# pcm register map
Vendor: Texas Instruments
Peripheral module from a debugger description file (folder MSP432).
Registers are 32-bit, read-write, no defined reset value unless marked. A register's access mark holds for its fields unless they carry their own. Offsets are as the file gives them; lines under a group give offsets from that group; [hi:lo] are bit positions; {n}, {i} and the like mark numbered series; 'fields as' and 'values as' point back to an identical list; <NAME> marks a mode.

## PCM
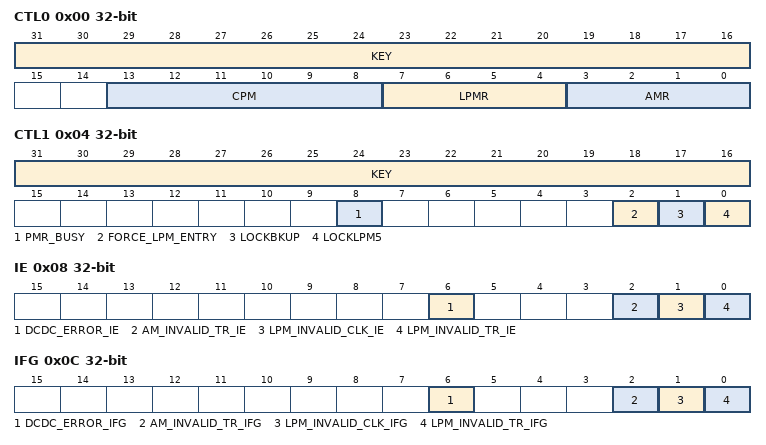
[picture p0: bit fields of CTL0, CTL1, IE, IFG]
0x00 CTL0 — Control 0 Register
  [31:16] KEY — PCM key
  [13:8] CPM — Current Power Mode
    0=CPM__0 (LDO based Active Mode at Core voltage setting 0.); 1=CPM__1 (LDO based Active Mode at Core voltage setting 1.); 4=CPM__4 (DC-DC based Active Mode at Core voltage setting 0.); 5=CPM__5 (DC-DC based Active Mode at Core voltage setting 1.); 8=CPM__8 (Low-Frequency Active Mode at Core voltage setting 0.); 9=CPM__9 (Low-Frequency Active Mode at Core voltage setting 1.); 16=CPM__22 (LDO based LPM0 at Core voltage setting 0.); 17=CPM__23 (LDO based LPM0 at Core voltage setting 1.); 20=CPM__32 (DC-DC based LPM0 at Core voltage setting 0.); 21=CPM__33 (DC-DC based LPM0 at Core voltage setting 1.); 24=CPM__36 (Low-Frequency LPM0 at Core voltage setting 0.); 25=CPM__37 (Low-Frequency LPM0 at Core voltage setting 1.); 32=CPM__50 (LPM3)
  [7:4] LPMR — Low Power Mode Request
    0=LPMR__0 (LPM3); 10=LPMR__16 (LPM3.5. Core voltage setting 0.); 12=LPMR__18 (LPM4.5)
  [3:0] AMR — Active Mode Request
    0=AMR__0 (LDO based Active Mode at Core voltage setting 0.); 1=AMR__1 (LDO based Active Mode at Core voltage setting 1.); 4=AMR__4 (DC-DC based Active Mode at Core voltage setting 0.); 5=AMR__5 (DC-DC based Active Mode at Core voltage setting 1.); 8=AMR__8 (Low-Frequency Active Mode at Core voltage setting 0.); 9=AMR__9 (Low-Frequency Active Mode at Core voltage setting 1.)
0x04 CTL1 — Control 1 Register
  [31:16] KEY — PCM key
  [8] PMR_BUSY — Power mode request busy flag
  [2] FORCE_LPM_ENTRY — Bit selection for the application to determine whether the entr
    0=FORCE_LPM_ENTRY__0 (PCM aborts LPM3/LPMx); 1=FORCE_LPM_ENTRY__1 (PCM enters LPM3/LPMx)
  [1] LOCKBKUP — Lock Backup
    0=LOCKBKUP__0 (Backup domain configuration defaults to reset condition); 1=LOCKBKUP__1 (Backup domain configuration remains locked during LPM3)
  [0] LOCKLPM5
    0=LOCKLPM5__0 (LPMx.5 configuration defaults to reset condition); 1=LOCKLPM5__1 (LPMx.5 configuration remains locked during LPMx.5 entry and exit)
0x08 IE — Interrupt Enable Register
  [6] DCDC_ERROR_IE — DC-DC error interrupt enable
    0=DCDC_ERROR_IE__0 (Disabled); 1=DCDC_ERROR_IE__1 (Enabled)
  [2] AM_INVALID_TR_IE — Active mode invalid transition interrupt enable
    0=AM_INVALID_TR_IE__0 (Disabled); 1=AM_INVALID_TR_IE__1 (Enabled)
  [1] LPM_INVALID_CLK_IE — LPM invalid clock interrupt enable
    0=LPM_INVALID_CLK_IE__0 (Disabled); 1=LPM_INVALID_CLK_IE__1 (Enabled)
  [0] LPM_INVALID_TR_IE — LPM invalid transition interrupt enable
    0=LPM_INVALID_TR_IE__0 (Disabled); 1=LPM_INVALID_TR_IE__1 (Enabled)
0x0C IFG — Interrupt Flag Register
  [6] DCDC_ERROR_IFG — DC-DC error flag
  [2] AM_INVALID_TR_IFG — Active mode invalid transition flag
  [1] LPM_INVALID_CLK_IFG — LPM invalid clock flag
  [0] LPM_INVALID_TR_IFG — LPM invalid transition flag
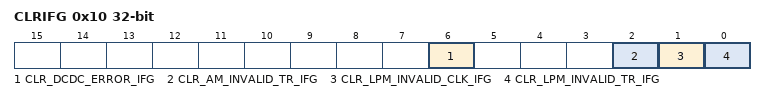
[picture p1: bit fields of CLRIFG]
0x10 CLRIFG — Clear Interrupt Flag Register
  [6] CLR_DCDC_ERROR_IFG — Clear DC-DC error flag.
  [2] CLR_AM_INVALID_TR_IFG — Clear active mode invalid transition flag.
  [1] CLR_LPM_INVALID_CLK_IFG — Clear LPM invalid clock flag
  [0] CLR_LPM_INVALID_TR_IFG — Clear LPM invalid transition flag
